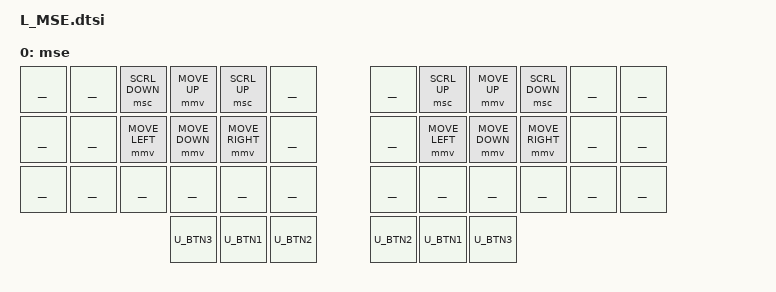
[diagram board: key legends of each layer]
/**
 *  Mouse Layer
 */
#include <dt-bindings/zmk/mouse.h>

// Settings tuned for 3840 x 2160 display resolution
#define ZMK_POINTING_DEFAULT_MOVE_VAL 600 // 600
#define ZMK_POINTING_DEFAULT_SCRL_VAL 20  // 10

#include <dt-bindings/zmk/pointing.h>
#include <input/processors.dtsi>
#include <zephyr/dt-bindings/input/input-event-codes.h>

// Based on @caksoylar's config, defaults in comments
&mmv {
  acceleration-exponent = <1>;      // 1
  time-to-max-speed-ms = <500>;    // 300
  delay-ms = <0>;                   // 0
};

&msc {
    acceleration-exponent = <1>;      // 0
    time-to-max-speed-ms = <40>;      // 300
    delay-ms = <0>;                   // 0
};

&mmv_input_listener {
  warp {
    layers = <NAV>;
    input-processors = <&zip_xy_scaler 3 1>;
  };
  precision {
    layers = <FN>;
    input-processors = <&zip_xy_scaler 1 2>;
  };
};

/ {
  zip_scroll_scaler: zip_scroll_scaler {
    compatible = "zmk,input-processor-scaler";
    #input-processor-cells = <2>;
    type = <INPUT_EV_REL>;
    codes = <INPUT_REL_WHEEL INPUT_REL_HWHEEL>;
    track-remainders;
  };
};

&msc_input_listener {
  warp {
    layers = <NAV>;
    input-processors = <&zip_scroll_scaler 2 1>;
  };
  precision {
    layers = <FN>;
    input-processors = <&zip_scroll_scaler 1 2>;
  };
};

#define U_MS_U &mmv MOVE_UP
#define U_MS_D &mmv MOVE_DOWN
#define U_MS_L &mmv MOVE_LEFT
#define U_MS_R &mmv MOVE_RIGHT
#define U_WH_U &msc SCRL_UP
#define U_WH_D &msc SCRL_DOWN
#define U_WH_L &msc SCRL_LEFT
#define U_WH_R &msc SCRL_RIGHT

ZMK_LAYER(mse,
// ╭───────────────┬───────────────┬───────────────┬───────────────┬───────────────┬───────────────╮   ╭───────────────┬───────────────┬───────────────┬───────────────┬───────────────┬───────────────╮
    ___             ___             U_WH_D          U_MS_U          U_WH_U          ___                 ___             U_WH_U          U_MS_U          U_WH_D          ___             ___
// ├───────────────┼───────────────├───────────────┼───────────────┼───────────────┼───────────────┤   ├───────────────├───────────────┼───────────────┼───────────────┼───────────────┼───────────────┤
    ___             ___             U_MS_L          U_MS_D          U_MS_R          ___                 ___             U_MS_L          U_MS_D          U_MS_R          ___             ___
// ├───────────────┼───────────────├───────────────┼───────────────┼───────────────┼───────────────┤   ├───────────────├───────────────┼───────────────┼───────────────┼───────────────┼───────────────┤
    ___             ___             ___             ___             ___             ___                 ___             ___             ___             ___             ___             ___
// ╰───────────────┴───────────────┴───────────────┼───────────────┼───────────────┼───────────────┤   ├───────────────├───────────────┼───────────────┼───────────────┴───────────────┴───────────────╯
                                                    U_BTN3          U_BTN1          U_BTN2              U_BTN2          U_BTN1          U_BTN3        
//                                                 ╰───────────────┴───────────────┴───────────────╯   ╰───────────────┴───────────────┴───────────────╯
)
